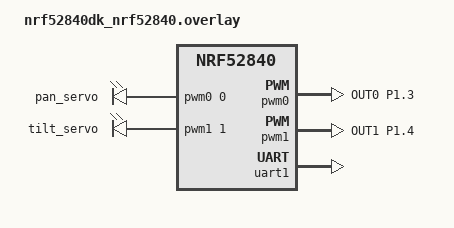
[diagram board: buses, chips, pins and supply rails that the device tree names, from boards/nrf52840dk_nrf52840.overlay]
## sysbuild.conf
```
# enable MCUboot using sysbuild
SB_CONFIG_BOOTLOADER_MCUBOOT=y
```

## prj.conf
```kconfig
CONFIG_MAIN_STACK_SIZE=4096

CONFIG_GPIO=y
CONFIG_PWM=y

CONFIG_SERIAL=y
CONFIG_UART_INTERRUPT_DRIVEN=y

CONFIG_SHELL=y
CONFIG_SHELL_WILDCARD=n

CONFIG_LOG=y
CONFIG_LOG_CMDS=y

CONFIG_JWT=y

CONFIG_FILE_SYSTEM=y
CONFIG_FILE_SYSTEM_SHELL=y
CONFIG_FILE_SYSTEM_SHELL_MOUNT_COMMAND=y
CONFIG_FILE_SYSTEM_SHELL_TEST_COMMANDS=y
CONFIG_FILE_SYSTEM_LITTLEFS=y

CONFIG_FLASH=y
CONFIG_FLASH_MAP=y
CONFIG_MPU_ALLOW_FLASH_WRITE=y

CONFIG_BT=y
CONFIG_BT_OBSERVER=y
CONFIG_BT_PERIPHERAL=y

# # Enable Extended Scanning
CONFIG_BT_EXT_ADV=y
# Maximum Extended Scanning buffer size
CONFIG_BT_EXT_SCAN_BUF_SIZE=1650
# Zephyr Bluetooth LE Controller needs 16 event buffers to generate Extended
# Advertising Report for receiving the complete 1650 bytes of data
CONFIG_BT_BUF_EVT_RX_COUNT=16
# Set maximum scan data length for Extended Scanning in Bluetooth LE Controller
CONFIG_BT_CTLR_SCAN_DATA_LEN_MAX=1650


CONFIG_BT_EXT_ADV_MAX_ADV_SET=2
CONFIG_BT_USER_PHY_UPDATE=y
CONFIG_BT_CTLR_ADVANCED_FEATURES=y
# Enable Advertising Data chaining in Zephyr Bluetooth LE Controller
CONFIG_BT_CTLR_ADV_DATA_CHAIN=y
CONFIG_BT_CTLR_ADV_DATA_LEN_MAX=1650
# Increase Advertising PDU buffers to number of advertising sets times the
# number of chain PDUs per advertising set when using Zephyr Bluetooth LE
# Controller
CONFIG_BT_CTLR_ADV_DATA_BUF_MAX=2
# Increase Zephyr Bluetooth LE Controller Rx buffer to receive complete chain of PDUs
CONFIG_BT_CTLR_RX_BUFFERS=9

CONFIG_LOG_BUFFER_SIZE=4096
```

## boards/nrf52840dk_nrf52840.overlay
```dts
/ {
    servos {
        compatible = "pwm-leds";
        pan_servo: pan_servo {
            pwms = <&pwm0 0 PWM_MSEC(20) PWM_POLARITY_NORMAL>;
        };
        tilt_servo: tilt_servo {
            pwms = <&pwm1 1 PWM_MSEC(20) PWM_POLARITY_NORMAL>;
        };
    };
};

&pinctrl {
	pwm0_servo: pwm0_servo {
		group1 {
			psels = <NRF_PSEL(PWM_OUT0, 1, 3)>;
			nordic,invert;
		};
    };

	pwm1_servo: pwm1_servo {
		group1 {
			psels = <NRF_PSEL(PWM_OUT1, 1, 4)>;
			nordic,invert;
		};
    };
};

&pwm0 {
    status = "okay";
	pinctrl-0 = <&pwm0_servo>;
	/delete-property/ pinctrl-1;
	pinctrl-names = "default";
};

&pwm1 {
    status = "okay";
	pinctrl-0 = <&pwm1_servo>;
	/delete-property/ pinctrl-1;
	pinctrl-names = "default";
};


espat_uart: &uart1 {
    status = "okay";
};
```

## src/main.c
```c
#include <zephyr/kernel.h>
#include <zephyr/device.h>

#include "filesystem.h"
#include "bt_interface.h"
#include "servo.h"

int main() {
    mount_filesystem();

    set_pan_angle(PAN_HOME);
    set_tilt_angle(TILT_DAM_UP);

    bt_run();
}
```

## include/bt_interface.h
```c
#ifndef BT_INTERFACE_H
#define BT_INTERFACE_H

#include <zephyr/kernel.h>
#include <stdint.h>

int bt_run(void);

extern uint8_t flags;
extern uint32_t current_time;

extern struct k_sem timer_access;

#endif // BT_INTERFACE_H
```

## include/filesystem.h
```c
#ifndef FILESYSTEM_H
#define FILESYSTEM_H

#include "sensordata.h"

int mount_filesystem(void);
void file_log_sensor_data(struct SensorData *data);
void file_log_enable(char *filepath);
void file_log_disable();

#endif // FILESYSTEM_H
```

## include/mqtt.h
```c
#ifndef MQTT_H
#define MQTT_H

#include <zephyr/kernel.h>

extern struct k_msgq queue_pub_mqtt;

void espat_send(char *str);
void espat_sanitize_arg(char *str, char *outbuf);
void espat_mqtt_configure(char *clientId, char *username, char *password);
void espat_mqtt_connect(char *ip, char *port);
void espat_wifi_connect(char *ssid, char *psk);
void espat_mqtt_publish(char *topic, char *message);

#endif // MQTT_H
```

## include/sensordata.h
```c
#ifndef SENSORDATA_H
#define SENSORDATA_H

#include <stdint.h>

extern struct k_msgq queue_sensor_data;

struct SensorData {
    int nodeId;
    uint32_t timestamp;
    uint32_t temperature;
    uint32_t pressure;
    uint32_t moisture;
};

void encode_sensor_data(struct SensorData *data, char *buf, int bufSize);

void set_setpoint(int val);
int get_setpoint(void);

#endif // SENSORDATA_H
```

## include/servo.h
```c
#ifndef SERVO_H
#define SERVO_H

#include <stdint.h>

#define PAN_HOME 25
#define TILT_DAM_UP 65
#define TILT_DAM_DOWN 155

void set_pan_angle(uint32_t angle);
void set_tilt_angle(uint32_t angle);

#endif // SERVO_H
```

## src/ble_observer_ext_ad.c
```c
/*
 * Copyright (c) 2022 Nordic Semiconductor ASA
 * Copyright (c) 2015-2016 Intel Corporation
 *
 * SPDX-License-Identifier: Apache-2.0
 */

// MODIFIED FROM SAMPLE CODE, ADDED RSSI THRESHOLD, DATA PARSING, NODE SELECTION

#include <stdint.h>
#include <zephyr/kernel.h>
#include <zephyr/logging/log.h>

#include <zephyr/bluetooth/bluetooth.h>
#include <zephyr/bluetooth/hci.h>
#include <string.h>

#include "sensordata.h"

LOG_MODULE_REGISTER(basenode_bt_obs);

#define NAME_LEN 30
#define RSSI_THRESHOLD -40 // RSSI threshold for filtering devices

// array of MAC addresses to filter
const char *nodes_of_interest[] = {
	"DC:B1:BE:10:38:1E (random)"
	//"E4:41:28:44:C6:DE (random)"
	//"C5:84:32:CA:99:CA (random)"
};

// structure to store sensordata from various nodes scraped
struct node_of_interest {
	char mac_id[NAME_LEN];
	// timestamp
	uint32_t timestamp;
	uint8_t counter;
	int16_t temperature_raw;
	uint16_t battery_mv;
};
// store all sensordata scraped from the nodes of interest
struct node_of_interest nodes[10]; // array of 10 nodes

/*
const bt_addr_le_t target_addr = {
	.type = BT_ADDR_LE_RANDOM, 
	.a = { .val = {0xC5, 0x84, 0x32, 0xCA, 0x99, 0xCA} }
};
*/

#define SENSOR_DATA_SIZE 12
#define SENSOR_PACKETS_PER_PAYLOAD 20

#define TIMESTAMP_OFFSET 0
#define MEAS_ID_OFFSET 4
#define MOISTURE_OFFSET 6
#define TEMP_OFFSET 8
#define PRESSURE_OFFSET 10

#define PRESSURE_BASE 100000

//#define MAX_MEASID_JUMP 50

uint16_t greatestReceivedMeasId = 0;

int numPacketsParsed = 0;

void parse_sensor_payload(const uint8_t *payload) {
    uint8_t nodeId = payload[0];

    uint8_t isFirst = numPacketsParsed == 0;

    for (int i = 0; i < (isFirst ? SENSOR_PACKETS_PER_PAYLOAD - 1 : SENSOR_PACKETS_PER_PAYLOAD); i++) {
        int pos = (isFirst ? SENSOR_DATA_SIZE : 0) + i * SENSOR_DATA_SIZE;

        uint32_t timestamp = *((uint32_t *) (void *) &payload[pos]);
        uint16_t measId = *((uint16_t *) (void *) &payload[pos + MEAS_ID_OFFSET]);
        uint16_t moisture = *((uint16_t *) (void *) &payload[pos + MOISTURE_OFFSET]);
        uint16_t temp = *((uint16_t *) (void *) &payload[pos + TEMP_OFFSET]);
        uint32_t pressure = *((int16_t *) (void *) &payload[pos + PRESSURE_OFFSET]) + PRESSURE_BASE;

        if (measId <= greatestReceivedMeasId) {
            continue;
        }

        greatestReceivedMeasId = measId;

        // load sensor data struct
        struct SensorData data;
        data.nodeId = nodeId;
        data.timestamp = timestamp;
        data.moisture = moisture;
        data.pressure = pressure;
        data.temperature = temp;

        k_msgq_put(&queue_sensor_data, &data, K_NO_WAIT);
        
        LOG_INF("Sensor Data (ID %u) - Time: %u, Moisture: %u, Temp: %u, Pressure: %d",
               measId, timestamp, moisture, temp, pressure);
    }
}

static bool parse_ad_data(struct bt_data *data, void *user_data) {

    if (data->type == BT_DATA_MANUFACTURER_DATA && data->data_len >= 5) {
        //LOG_INF("recvd %d\n", data->data_len);

        const uint8_t *payload = data->data;

        parse_sensor_payload(payload);
        numPacketsParsed = (numPacketsParsed + 1) % 3;

        /*
		printf("\t \t [DEBUG] Raw AD data: ");
		for (int i = 0; i < data->data_len; i++) {
			printf("%02X ", payload[i]);
		}
		printk("\n");
        */
    }
    return true;
}

// static void device_found(const bt_addr_le_t *addr, int8_t rssi, uint8_t type, struct net_buf_simple *ad) {
	
// 	if (rssi < RSSI_THRESHOLD) {
// 		return; // Ignore weak signals
// 	}
	
// 	char addr_str[BT_ADDR_LE_STR_LEN];

// 	bt_addr_le_to_str(addr, addr_str, sizeof(addr_str));
// 	LOG_INF("Device found: %s (RSSI %d), type %u, AD data len %u\n",
// 	       addr_str, rssi, type, ad->len);

// 	// Parse the advertisement data if the device is of interest
// 	for (uint8_t i = 0; i < sizeof(nodes_of_interest) / sizeof(nodes_of_interest[0]); i++) {
// 		if (strcmp(addr_str, nodes_of_interest[i]) == 0) {
// 			//LOG_INF("Found target device: %s\n", addr_str);
// 			bt_data_parse(ad, parse_ad_data, NULL);
// 			k_sleep(K_MSEC(1000));
// 			//return;
// 		}
// 	}	
	
// }

#if defined(CONFIG_BT_EXT_ADV)
	// static bool data_cb(struct bt_data *data, void *user_data) {
	// 	char *name = user_data;
	// 	uint8_t len;

	// 	switch (data->type) {
	// 		case BT_DATA_NAME_SHORTENED:
	// 		case BT_DATA_NAME_COMPLETE:
	// 			len = MIN(data->data_len, NAME_LEN - 1);
	// 			(void)memcpy(name, data->data, len);
	// 			name[len] = '\0';
	// 			return false;
	// 		default:
	// 			return true;
	// 	}
	// }

	// static const char *phy2str(uint8_t phy) {
	// 	switch (phy) {
	// 	case BT_GAP_LE_PHY_NONE: return "No packets";
	// 	case BT_GAP_LE_PHY_1M: return "LE 1M";
	// 	case BT_GAP_LE_PHY_2M: return "LE 2M";
	// 	case BT_GAP_LE_PHY_CODED: return "LE Coded";
	// 	default: return "Unknown";
	// 	}
	// }

	static void scan_recv(const struct bt_le_scan_recv_info *info, struct net_buf_simple *buf) {
		
		if (info->rssi < RSSI_THRESHOLD) {
			//LOG_INF("Ignoring weak signal from %s (RSSI %d)\n", le_addr, info->rssi);
			return; // Ignore weak signals
		}

        if (!(info->adv_props & BT_GAP_ADV_PROP_EXT_ADV)) {
            return; // Skip non-extended (legacy) advertising
        }
		
		char le_addr[BT_ADDR_LE_STR_LEN];

		bt_addr_le_to_str(info->addr, le_addr, sizeof(le_addr));
		//LOG_INF("[DEVICE]: %s, RSSI: %d, Data len: %u\n", le_addr, info->rssi, buf->len);

		//data_status = BT_HCI_LE_ADV_EVT_TYPE_DATA_STATUS(info->adv_props);

		
		// LOG_INF("[DEVICE]: %s, AD evt type %u, Tx Pwr: %i, RSSI %i "
		// 	"Data status: %u, AD data len: %u Name: %s "
		// 	"C:%u S:%u D:%u SR:%u E:%u Pri PHY: %s, Sec PHY: %s, "
		// 	"Interval: 0x%04x (%u ms), SID: %u\n",
		// 	le_addr, info->adv_type, info->tx_power, info->rssi,
		// 	data_status, data_len, name,
		// 	(info->adv_props & BT_GAP_ADV_PROP_CONNECTABLE) != 0,
		// 	(info->adv_props & BT_GAP_ADV_PROP_SCANNABLE) != 0,
		// 	(info->adv_props & BT_GAP_ADV_PROP_DIRECTED) != 0,
		// 	(info->adv_props & BT_GAP_ADV_PROP_SCAN_RESPONSE) != 0,
		// 	(info->adv_props & BT_GAP_ADV_PROP_EXT_ADV) != 0,
		// 	phy2str(info->primary_phy), phy2str(info->secondary_phy),
		// 	info->interval, info->interval * 5 / 4, info->sid);

		for (uint8_t i = 0; i < sizeof(nodes_of_interest) / sizeof(nodes_of_interest[0]); i++) {
			if (strcmp(le_addr, nodes_of_interest[i]) == 0) {
				bt_data_parse(buf, parse_ad_data, NULL);
				k_sleep(K_MSEC(1000));
			}
		}

	}

	static struct bt_le_scan_cb scan_callbacks = {
		.recv = scan_recv,
	};
#endif /* CONFIG_BT_EXT_ADV */

int observer_start(void) {

	struct bt_le_scan_param scan_param = {
		.type       = BT_LE_SCAN_TYPE_PASSIVE,
		//.options    = BT_LE_SCAN_OPT_FILTER_DUPLICATE,
		.interval   = BT_GAP_SCAN_FAST_INTERVAL,
		.window     = BT_GAP_SCAN_FAST_WINDOW,
	};
	int err;

	#if defined(CONFIG_BT_EXT_ADV)
		// Only applies for BLE using extended advertising
		bt_le_scan_cb_register(&scan_callbacks);
		LOG_INF("Registered scan callbacks\n");
	#endif /* CONFIG_BT_EXT_ADV */

	err = bt_le_scan_start(&scan_param, NULL); // do nothing if legacy ble device found (previously calls device_found)
	if (err) {
		LOG_INF("Start scanning failed (err %d)\n", err);
		return err;
	}
	LOG_INF("Started scanning...\n");

	return 0;
}
```

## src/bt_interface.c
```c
/*
* TODO: 
* - Merge with encoding from sensornode
*/

#include <zephyr/kernel.h>
#include <zephyr/logging/log.h>

#include <zephyr/bluetooth/bluetooth.h>
#include <zephyr/bluetooth/hci.h>

LOG_MODULE_REGISTER(basenode_bt);

#define SENSOR_ADV_INTERVAL_MS 1000
#define DEVICE_NAME "BaseNode"

K_SEM_DEFINE(timer_access, 1, 1); // Semaphore for synchronization

int observer_start(void);

static uint8_t basenode_adv_payload_general[5] = {0};  // Room for mobile node data
static struct bt_data ad[] = {
    BT_DATA_BYTES(BT_DATA_FLAGS, (BT_LE_AD_GENERAL | BT_LE_AD_NO_BREDR)),
	BT_DATA(BT_DATA_NAME_COMPLETE, DEVICE_NAME, sizeof(DEVICE_NAME) - 1),
    BT_DATA(BT_DATA_MANUFACTURER_DATA, basenode_adv_payload_general, sizeof(basenode_adv_payload_general)),
};

// Mobile Node Data
static struct k_timer second_timer;
uint32_t current_time = 0;
uint8_t flags = 0x03; // Polling Rate (hrs) / Disable Sensors

void timer_handler(struct k_timer *dummy) {
    
	k_sem_take(&timer_access, K_FOREVER);
	current_time += 1;
	// Wraparound once max value reached
	if (current_time >= 0xFFFFFFFF) {
        current_time = 1;  // Reset to 1 to avoid zero timestamp
    }
	k_sem_give(&timer_access); 
}

// Function to update the mobile node's advertising payload
static void update_base_adv_payload_general(void) {
	// Update the advertising payload with the current time
	
	k_sem_take(&timer_access, K_FOREVER); // Wait for access to the timer
	basenode_adv_payload_general[0] = (current_time >> 0) & 0xFF;   // Byte 0 (LSB)
    basenode_adv_payload_general[1] = (current_time >> 8) & 0xFF;   
    basenode_adv_payload_general[2] = (current_time >> 16) & 0xFF;  
    basenode_adv_payload_general[3] = (current_time >> 24) & 0xFF;
	basenode_adv_payload_general[4] = flags;  
	k_sem_give(&timer_access); // Allow access to the timer

	// Print updated count value and flags
	//LOG_INF("BaseNode Adv Payload Updated: Time: %u, Flags: 0x%02X\n", current_time, flags);
}

int bt_run(void) {
	
	int err;
	LOG_INF("Starting BaseNode...\n");

	k_timer_init(&second_timer, timer_handler, NULL);
    k_timer_start(&second_timer, K_SECONDS(1), K_SECONDS(1));

	// Initialise the Bluetooth Subsystem 
	err = bt_enable(NULL);
	if (err) {
		LOG_INF("Bluetooth init failed (err %d).\n", err);
		return -1;
	}

	// Start scanner
	(void) observer_start();

	// Begin advertising
	err = bt_le_adv_start(
		BT_LE_ADV_PARAM(
			BT_LE_ADV_OPT_USE_IDENTITY,
			BT_GAP_ADV_FAST_INT_MIN_2,
			BT_GAP_ADV_FAST_INT_MAX_2,
			NULL),
		ad, ARRAY_SIZE(ad), NULL, 0);
    if (err) {
        LOG_INF("Advertising failed to start (err %d).\n", err);
        return -1;
    }

	while (1) {
        update_base_adv_payload_general();
        bt_le_adv_update_data(ad, ARRAY_SIZE(ad), NULL, 0);
        k_sleep(K_MSEC(SENSOR_ADV_INTERVAL_MS));
    }

	LOG_INF("Exiting %s thread.\n", __func__);

	return 0;
}
```

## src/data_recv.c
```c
#include <zephyr/kernel.h>

#include <stdint.h>

#include "sensordata.h"

#define DATA_RECV_STACK_SIZE 4096
#define DATA_RECV_PRIORITY 2

#define DATA_RECV_QUEUE_SIZE 100

K_MSGQ_DEFINE(queue_sensor_data, sizeof(struct SensorData), DATA_RECV_QUEUE_SIZE, 1);
```

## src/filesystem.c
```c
#include <stdio.h>
#include <string.h>
#include <zephyr/kernel.h>
#include <zephyr/logging/log.h>

#include <zephyr/fs/fs.h>
#include <zephyr/fs/littlefs.h>
#include <zephyr/storage/flash_map.h>

#include "sensordata.h"
#include "zephyr/sys/printk.h"

LOG_MODULE_REGISTER(basenode_fs);

#define STORAGE_PARTITION_ID FIXED_PARTITION_ID(storage_partition)
FS_LITTLEFS_DECLARE_DEFAULT_CONFIG(lfs_data);

#define SENSOR_DATA_FILENAME_BUFLEN 256
#define SENSOR_LOG_BUF_LEN 256

char sensorDataFileName[SENSOR_DATA_FILENAME_BUFLEN];

bool sensorLoggingEnabled = false;

static struct fs_mount_t mountPoint = {
    .type = FS_LITTLEFS,
    .fs_data = &lfs_data,
    .storage_dev = (void *)STORAGE_PARTITION_ID,
    .mnt_point = "/lfs"
};

int mount_filesystem(void) {
    int rc;

    // mount littlefs filesystem
    rc = fs_mount(&mountPoint);

    if (rc < 0) {
        return rc;
    }

    return 0;
}

void file_log_enable(char *filepath) {
    strncpy(sensorDataFileName, filepath, SENSOR_DATA_FILENAME_BUFLEN);
    sensorLoggingEnabled = true;
}

void file_log_disable() {
    sensorLoggingEnabled = false;
}

void file_log_sensor_data(struct SensorData *data) {
    int rc;

    // only log if enabled
    if (!sensorLoggingEnabled) {
        return;
    }

    struct fs_file_t logFile;
    fs_file_t_init(&logFile);

    char buf[SENSOR_LOG_BUF_LEN];

    rc = fs_open(&logFile, sensorDataFileName, FS_O_CREATE | FS_O_APPEND);
    if (rc < 0) {
        LOG_ERR("error: cannot open sensor log file");
        return;
    }

    encode_sensor_data(data, buf, SENSOR_LOG_BUF_LEN); 

    rc = fs_write(&logFile, buf, strlen(buf));
    if (rc < 0) {
        LOG_ERR("error: sensor log file cannot be written");
        return;
    }

    // add a newline at the end
    const char nl = '\n';
    fs_write(&logFile, &nl, 1);

    fs_close(&logFile); 
}
```

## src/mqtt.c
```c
#include <zephyr/kernel.h>
#include <zephyr/device.h>
#include <zephyr/drivers/uart.h>
#include <zephyr/logging/log.h>

#include <string.h>

#include "sensordata.h"

LOG_MODULE_REGISTER(espat_mqtt);

static const struct device *const espat_uart = DEVICE_DT_GET(DT_NODELABEL(espat_uart));

#define MSG_SIZE 100
#define ESP_MSG_BUF_SIZE 256
#define SENSOR_QUEUE_SIZE 50

#define NUM_ESPAT_TERMINATORS 4

// queue to store uart messages from ESP-AT
K_MSGQ_DEFINE(queue_espat_uart, MSG_SIZE, 10, 4);

// queue to store sensor data to be published
K_MSGQ_DEFINE(queue_pub_mqtt, sizeof(struct SensorData), SENSOR_QUEUE_SIZE, 1);

// semaphore to tell when ESP-AT is available
K_SEM_DEFINE(sem_espat, 1, 1);

// rx buffer for uart messages
static char rx_buf[MSG_SIZE];
static int rx_buf_pos;

char *espatTerminators[NUM_ESPAT_TERMINATORS] = {
    "OK",
    "ERROR",
    "+MQTTPUB:OK",
    "WIFI GOT IP"
};

int x = sizeof(espatTerminators);

void serial_cb(const struct device *dev, void *user_data)
{
	uint8_t c;

	if (!uart_irq_update(espat_uart)) {
		return;
	}

	if (!uart_irq_rx_ready(espat_uart)) {
		return;
	}

	while (uart_fifo_read(espat_uart, &c, 1) == 1) {
        if ((c == '\n' || c == '\r') && rx_buf_pos > 0) {
            rx_buf[rx_buf_pos] = '\0';
            k_msgq_put(&queue_espat_uart, &rx_buf, K_NO_WAIT);
            rx_buf_pos = 0;
        } 
        else if ((c == '\n' || c == '\r') && rx_buf_pos == 0) {
            continue; // ignore newlines before anything else
        }
        else if (rx_buf_pos < (sizeof(rx_buf) - 1)) {
            rx_buf[rx_buf_pos++] = c;
        }
	}
}

void espat_send(char *str) {
    k_sem_take(&sem_espat, K_FOREVER);

    for (char *c = str; *c != '\0'; c++) {
        uart_poll_out(espat_uart, *c);
    }
    uart_poll_out(espat_uart, '\r');
    uart_poll_out(espat_uart, '\n');
}

void espat_mqtt_configure(char *clientId, char *username, char *password) {
    char buf[ESP_MSG_BUF_SIZE];

    snprintf(
            buf, ESP_MSG_BUF_SIZE, "AT+MQTTUSERCFG=0,1,\"%s\",\"%s\",\"%s\",0,0,\"\"", 
            clientId, username, password
    );

    espat_send(buf);
}

void espat_mqtt_connect(char *ip, char *port) {
    char buf[ESP_MSG_BUF_SIZE];

    snprintf(buf, ESP_MSG_BUF_SIZE, "AT+MQTTCONN=0,\"%s\",%s,1", ip, port);
    espat_send(buf);
}

void espat_wifi_connect(char *ssid, char *psk) {
    char buf[ESP_MSG_BUF_SIZE];

    snprintf(buf, ESP_MSG_BUF_SIZE, "AT+CWMODE=1");
    espat_send(buf);

    snprintf(buf, ESP_MSG_BUF_SIZE, "AT+CWJAP=\"%s\",\"%s\"", ssid, psk);
    espat_send(buf);
}

void espat_mqtt_publish(char *topic, char *message) {
    char cmdBuf[ESP_MSG_BUF_SIZE];

    snprintf(cmdBuf, ESP_MSG_BUF_SIZE, "AT+MQTTPUBRAW=0,\"%s\",%d,1,0", topic, strlen(message));
    espat_send(cmdBuf);
    espat_send(message);
}

void espat_thread() {
    char tx_buf[MSG_SIZE];

    uart_irq_callback_user_data_set(espat_uart, serial_cb, NULL);
    uart_irq_rx_enable(espat_uart);

    while (k_msgq_get(&queue_espat_uart, &tx_buf, K_FOREVER) == 0) {
        // check if received data is a "terminator" that allows additional
        // messages to be sent to ESP-AT
        for (int i = 0; i < NUM_ESPAT_TERMINATORS; i++) {
            if (!strncmp(tx_buf, espatTerminators[i], strlen(espatTerminators[i]))) {
                k_sem_give(&sem_espat);
            }
        }

        LOG_INF("Rcvd from ESP-AT: %s", tx_buf);
	}
}

void mqtt_pub_thread() {

    struct SensorData sensorData;
    char sensorDataBuf[ESP_MSG_BUF_SIZE];

    while (1) {
        while (k_msgq_get(&queue_pub_mqtt, &sensorData, K_FOREVER) == 0) {
            encode_sensor_data(&sensorData, sensorDataBuf, ESP_MSG_BUF_SIZE);
            espat_mqtt_publish("sensors", sensorDataBuf);
        }

        k_msleep(10);
    }
}

K_THREAD_DEFINE(espat_tid, 4096, espat_thread, NULL, NULL, NULL, 2, 0, 0);
K_THREAD_DEFINE(mqtt_pub_tid, 4096, mqtt_pub_thread, NULL, NULL, NULL, 2, 0, 0);
```

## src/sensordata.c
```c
#include <stdint.h>
#include <zephyr/kernel.h>
#include <zephyr/data/json.h>

#include "sensordata.h"
#include "mqtt.h"
#include "filesystem.h"
#include "servo.h"

#include "zephyr/logging/log.h"

LOG_MODULE_REGISTER(basenode_pid);

#define DATA_PROC_STACK_SIZE 4096
#define DATA_PROC_PRIORITY 2

#define Kp 0.01
#define Ki 0.002
#define Kd 0.05

#define ANGLE_OFFSET 25
#define ANGLE_SCALER 2.5

#define INTEGRAL_PREV_WEIGHT 0.05

K_MUTEX_DEFINE(mut_setpoint);

int setPoint = 1000;

void set_setpoint(int val) {
    k_mutex_lock(&mut_setpoint, K_FOREVER);
    setPoint = val;
    k_mutex_unlock(&mut_setpoint);
}

int get_setpoint(void) {
    int val;

    k_mutex_lock(&mut_setpoint, K_FOREVER);
    val = setPoint;
    k_mutex_unlock(&mut_setpoint);

    return val;
}

struct json_obj_descr sensor_data_descr[] = {
    JSON_OBJ_DESCR_PRIM(struct SensorData, nodeId, JSON_TOK_NUMBER),
    JSON_OBJ_DESCR_PRIM(struct SensorData, moisture, JSON_TOK_NUMBER),
    JSON_OBJ_DESCR_PRIM(struct SensorData, temperature, JSON_TOK_NUMBER),
    JSON_OBJ_DESCR_PRIM(struct SensorData, pressure, JSON_TOK_NUMBER),
    JSON_OBJ_DESCR_PRIM(struct SensorData, timestamp, JSON_TOK_NUMBER),
};

void encode_sensor_data(struct SensorData *data, char *buf, int bufSize) {
    json_obj_encode_buf(sensor_data_descr, 5, data, buf, bufSize);
}

void pid_update(int value, uint32_t time, int *angle) {
    static int prev_error = 0;
    static int prev_integral = 0;
    static uint32_t last_time = 0;

    k_mutex_lock(&mut_setpoint, K_FOREVER);
    int error = setPoint - value;
    k_mutex_unlock(&mut_setpoint);

    double dt = (time - last_time)/1000.0;

    if (dt == 0) {
        return;
    }

    double integral = Ki * (prev_integral + INTEGRAL_PREV_WEIGHT * error * dt);
    double derivative = ((double)(error - prev_error))/((double) dt);

    last_time = time;
    prev_integral = integral;
    prev_error = error;

    double pid = Kp*error + Ki*integral + Kd*derivative;


    double angleVal = ANGLE_SCALER * (ANGLE_OFFSET + pid) + TILT_DAM_UP;

    if (angleVal > TILT_DAM_DOWN) {
        angleVal = TILT_DAM_DOWN;
    }
    else if (angleVal < TILT_DAM_UP) {
        angleVal = TILT_DAM_UP;
    }

    *angle = (int) angleVal;

    LOG_INF("PID (error %d) (int %f) (deriv %f) (pid %f) (dt %f) (angle %f)", error, integral, derivative, pid, dt, angleVal);
}

void data_proc_thread() {
    struct SensorData data;

    int servoAngle = TILT_DAM_UP;

    while (k_msgq_get(&queue_sensor_data, &data, K_FOREVER) == 0) {
        file_log_sensor_data(&data);

        pid_update(data.moisture, data.timestamp, &servoAngle);
        set_tilt_angle(servoAngle);

        k_msgq_put(&queue_pub_mqtt, &data, K_FOREVER);
    }
}

K_THREAD_DEFINE(data_proc_tid, DATA_PROC_STACK_SIZE, data_proc_thread, NULL, NULL, NULL, DATA_PROC_PRIORITY, 0, 0);
```

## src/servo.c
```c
#include <zephyr/kernel.h>
#include <zephyr/device.h>
#include <zephyr/drivers/pwm.h>

#include <stdint.h>

static const struct pwm_dt_spec pan_servo = PWM_DT_SPEC_GET(DT_NODELABEL(pan_servo));
static const struct pwm_dt_spec tilt_servo = PWM_DT_SPEC_GET(DT_NODELABEL(tilt_servo));

#define SERVO_PW_US_MIN_ANGLE 400
#define SERVO_PW_US_MAX_ANGLE 2500

#define ANGLE_MIN 0
#define ANGLE_MAX 180

#define ANGLE_TO_PW(angle) (((angle) - ANGLE_MIN) * (SERVO_PW_US_MAX_ANGLE - SERVO_PW_US_MIN_ANGLE) / (ANGLE_MAX - ANGLE_MIN) + SERVO_PW_US_MIN_ANGLE)

void set_pan_angle(uint32_t angle) {
    if (angle < ANGLE_MIN || angle > ANGLE_MAX) {
        return;
    }

    pwm_set_pulse_dt(&pan_servo, PWM_USEC(ANGLE_TO_PW(angle)));
}

void set_tilt_angle(uint32_t angle) {
    if (angle < ANGLE_MIN || angle > ANGLE_MAX) {
        return;
    }

    pwm_set_pulse_dt(&tilt_servo, PWM_USEC(ANGLE_TO_PW(angle)));
}
```
